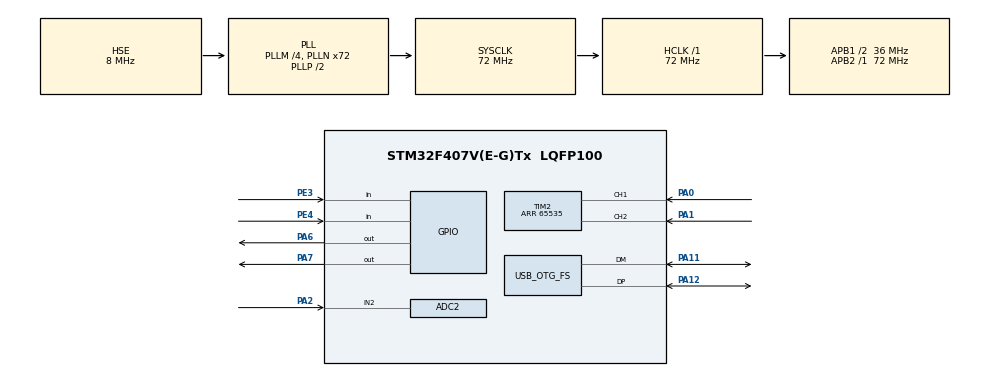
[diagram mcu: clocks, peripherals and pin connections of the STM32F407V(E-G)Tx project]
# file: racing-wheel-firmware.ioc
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ADC2.Channel-0\#ChannelRegularConversion=ADC_CHANNEL_2
ADC2.ClockPrescaler=ADC_CLOCK_SYNC_PCLK_DIV2
ADC2.ContinuousConvMode=ENABLE
ADC2.EOCSelection=ADC_EOC_SEQ_CONV
ADC2.InjNumberOfConversion=0
ADC2.NbrOfConversion=1
ADC2.NbrOfConversionFlag=1
ADC2.Rank-0\#ChannelRegularConversion=1
ADC2.Resolution=ADC_RESOLUTION_8B
ADC2.SamplingTime-0\#ChannelRegularConversion=ADC_SAMPLETIME_480CYCLES
Mcu.Family=STM32F4
Mcu.Name=STM32F407V(E-G)Tx
Mcu.Package=LQFP100
NVIC.OTG_FS_IRQn=true\:0\:0\:false\:false\:true\:false\:true\:true
NVIC.PriorityGroup=NVIC_PRIORITYGROUP_4
PA0-WKUP.Signal=S_TIM2_CH1_ETR
PA1.Signal=S_TIM2_CH2
PA11.Mode=Device_Only
PA11.Signal=USB_OTG_FS_DM
PA12.GPIO_PuPd=GPIO_NOPULL
PA12.Mode=Device_Only
PA12.Signal=USB_OTG_FS_DP
PA13.Mode=Trace_Asynchronous_SW
PA13.Signal=SYS_JTMS-SWDIO
PA14.Mode=Trace_Asynchronous_SW
PA14.Signal=SYS_JTCK-SWCLK
PA2.GPIO_PuPd=GPIO_NOPULL
PA2.Signal=ADCx_IN2
PA6.Signal=GPIO_Output
PA7.Signal=GPIO_Output
PB3.Mode=Trace_Asynchronous_SW
PB3.Signal=SYS_JTDO-SWO
PC14-OSC32_IN.Mode=LSE-External-Oscillator
PC14-OSC32_IN.Signal=RCC_OSC32_IN
PC15-OSC32_OUT.Mode=LSE-External-Oscillator
PC15-OSC32_OUT.Signal=RCC_OSC32_OUT
PE3.GPIO_PuPd=GPIO_PULLUP
PE3.Signal=GPIO_Input
PE4.GPIO_PuPd=GPIO_PULLUP
PE4.Signal=GPIO_Input
PH0-OSC_IN.Mode=HSE-External-Oscillator
PH0-OSC_IN.Signal=RCC_OSC_IN
PH1-OSC_OUT.Mode=HSE-External-Oscillator
PH1-OSC_OUT.Signal=RCC_OSC_OUT
ProjectManager.HeapSize=0x200
ProjectManager.StackSize=0x400
ProjectManager.TargetToolchain=STM32CubeIDE
RCC.48MHZClocksFreq_Value=48000000
RCC.AHBFreq_Value=72000000
RCC.APB1CLKDivider=RCC_HCLK_DIV2
RCC.APB1Freq_Value=36000000
RCC.APB1TimFreq_Value=72000000
RCC.APB2Freq_Value=72000000
RCC.APB2TimFreq_Value=72000000
RCC.CortexFreq_Value=72000000
RCC.HCLKFreq_Value=72000000
RCC.HSE_VALUE=8000000
RCC.HSI_VALUE=16000000
RCC.PLLM=4
RCC.PLLN=72
RCC.PLLQ=3
RCC.SYSCLKFreq_VALUE=72000000
RCC.SYSCLKSource=RCC_SYSCLKSOURCE_PLLCLK
RCC.VCOOutputFreq_Value=144000000
SH.ADCx_IN2.0=ADC2_IN2,IN2
SH.S_TIM2_CH1_ETR.0=TIM2_CH1,Encoder_Interface
SH.S_TIM2_CH2.0=TIM2_CH2,Encoder_Interface
TIM2.AutoReloadPreload=TIM_AUTORELOAD_PRELOAD_ENABLE
TIM2.EncoderMode=TIM_ENCODERMODE_TI12
TIM2.Period=65535
USB_DEVICE.CLASS_NAME_FS=CUSTOM_HID
USB_DEVICE.MANUFACTURER_STRING-CUSTOM_HID_FS=OMP
USB_DEVICE.PID_CUSTOMHID_FS=0x5750
USB_DEVICE.PRODUCT_STRING_CUSTOMHID_FS=OMP Racing wheel
USB_DEVICE.USBD_CUSTOMHID_OUTREPORT_BUF_SIZE-CUSTOM_HID_FS=64
USB_DEVICE.USBD_CUSTOM_HID_REPORT_DESC_SIZE-CUSTOM_HID_FS=46
USB_DEVICE.VID-CUSTOM_HID_FS=0x483
USB_DEVICE.VirtualMode-CUSTOM_HID_FS=CustomHid
USB_DEVICE.VirtualModeFS=Custom_Hid_FS
USB_OTG_FS.VirtualMode=Device_Only
VP_USB_DEVICE_VS_USB_DEVICE_CUSTOM_HID_FS.Mode=CUSTOM_HID_FS
board=custom

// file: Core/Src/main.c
/* USER CODE BEGIN Header */
/**
  ******************************************************************************
  * @file           : main.c
  * @brief          : Main program body
  ******************************************************************************
  * @attention
  *
  * Copyright (c) 2023 STMicroelectronics.
  * All rights reserved.
  *
  * This software is licensed under terms that can be found in the LICENSE file
  * in the root directory of this software component.
  * If no LICENSE file comes with this software, it is provided AS-IS.
  *
  ******************************************************************************
  */
/* USER CODE END Header */
#include "main.h"
#include "usb_device.h"

ADC_HandleTypeDef hadc2;

TIM_HandleTypeDef htim2;

void SystemClock_Config(void);
static void MX_GPIO_Init(void);
static void MX_ADC2_Init(void);
static void MX_TIM2_Init(void);

/* USER CODE BEGIN 0 */

// [DEBUG] printf
// _write is internally used by printf
// We point it to now use the Instrumentation Trace Macrocell (ITM)
// Which is wired to SWO
int _write(int file,char* data,int len){
    for(int i = 0;i<len;i++){
        ITM_SendChar(*data++);
    }
    return len;
}

/* USER CODE END 0 */

int main(void)
{

  /* MCU Configuration--------------------------------------------------------*/

  /* Reset of all peripherals, Initializes the Flash interface and the Systick. */
  HAL_Init();

  /* Configure the system clock */
  SystemClock_Config();

  /* USER CODE BEGIN SysInit */
  __HAL_RCC_TIM2_CLK_ENABLE();
  /* USER CODE END SysInit */

  /* Initialize all configured peripherals */
  MX_GPIO_Init();
  MX_USB_DEVICE_Init();
  MX_ADC2_Init();
  MX_TIM2_Init();

  /* Infinite loop */
  /* USER CODE BEGIN WHILE */
  while (1)
  {
      uint32_t enc = TIM2->CNT;
//      printf("Encoder Ticks = %lu\n\r", enc);
      HAL_ADC_PollForConversion(&hadc2, HAL_MAX_DELAY);
      uint32_t accel = HAL_ADC_GetValue(&hadc2);
//      printf("Accelerator = %lu\n\r", accel);

    /* USER CODE END WHILE */

  }
}

void SystemClock_Config(void)
{
  RCC_OscInitTypeDef RCC_OscInitStruct = {0};
  RCC_ClkInitTypeDef RCC_ClkInitStruct = {0};

  /** Configure the main internal regulator output voltage
  */
  __HAL_RCC_PWR_CLK_ENABLE();
  __HAL_PWR_VOLTAGESCALING_CONFIG(PWR_REGULATOR_VOLTAGE_SCALE1);

  /** Initializes the RCC Oscillators according to the specified parameters
  * in the RCC_OscInitTypeDef structure.
  */
  RCC_OscInitStruct.OscillatorType = RCC_OSCILLATORTYPE_HSE;
  RCC_OscInitStruct.HSEState = RCC_HSE_ON;
  RCC_OscInitStruct.PLL.PLLState = RCC_PLL_ON;
  RCC_OscInitStruct.PLL.PLLSource = RCC_PLLSOURCE_HSE;
  RCC_OscInitStruct.PLL.PLLM = 4;
  RCC_OscInitStruct.PLL.PLLN = 72;
  RCC_OscInitStruct.PLL.PLLP = RCC_PLLP_DIV2;
  RCC_OscInitStruct.PLL.PLLQ = 3;
  if (HAL_RCC_OscConfig(&RCC_OscInitStruct) != HAL_OK)
  {
    Error_Handler();
  }

  /** Initializes the CPU, AHB and APB buses clocks
  */
  RCC_ClkInitStruct.ClockType = RCC_CLOCKTYPE_HCLK|RCC_CLOCKTYPE_SYSCLK
                              |RCC_CLOCKTYPE_PCLK1|RCC_CLOCKTYPE_PCLK2;
  RCC_ClkInitStruct.SYSCLKSource = RCC_SYSCLKSOURCE_PLLCLK;
  RCC_ClkInitStruct.AHBCLKDivider = RCC_SYSCLK_DIV1;
  RCC_ClkInitStruct.APB1CLKDivider = RCC_HCLK_DIV2;
  RCC_ClkInitStruct.APB2CLKDivider = RCC_HCLK_DIV1;

  if (HAL_RCC_ClockConfig(&RCC_ClkInitStruct, FLASH_LATENCY_2) != HAL_OK)
  {
    Error_Handler();
  }
}

static void MX_ADC2_Init(void)
{

  ADC_ChannelConfTypeDef sConfig = {0};

  /** Configure the global features of the ADC (Clock, Resolution, Data Alignment and number of conversion)
  */
  hadc2.Instance = ADC2;
  hadc2.Init.ClockPrescaler = ADC_CLOCK_SYNC_PCLK_DIV2;
  hadc2.Init.Resolution = ADC_RESOLUTION_8B;
  hadc2.Init.ScanConvMode = DISABLE;
  hadc2.Init.ContinuousConvMode = ENABLE;
  hadc2.Init.DiscontinuousConvMode = DISABLE;
  hadc2.Init.ExternalTrigConvEdge = ADC_EXTERNALTRIGCONVEDGE_NONE;
  hadc2.Init.ExternalTrigConv = ADC_SOFTWARE_START;
  hadc2.Init.DataAlign = ADC_DATAALIGN_RIGHT;
  hadc2.Init.NbrOfConversion = 1;
  hadc2.Init.DMAContinuousRequests = DISABLE;
  hadc2.Init.EOCSelection = ADC_EOC_SEQ_CONV;
  if (HAL_ADC_Init(&hadc2) != HAL_OK)
  {
    Error_Handler();
  }

  /** Configure for the selected ADC regular channel its corresponding rank in the sequencer and its sample time.
  */
  sConfig.Channel = ADC_CHANNEL_2;
  sConfig.Rank = 1;
  sConfig.SamplingTime = ADC_SAMPLETIME_480CYCLES;
  if (HAL_ADC_ConfigChannel(&hadc2, &sConfig) != HAL_OK)
  {
    Error_Handler();
  }
  /* USER CODE BEGIN ADC2_Init 2 */
    HAL_ADC_Start(&hadc2);
  /* USER CODE END ADC2_Init 2 */

}

static void MX_TIM2_Init(void)
{

  TIM_Encoder_InitTypeDef sConfig = {0};
  TIM_MasterConfigTypeDef sMasterConfig = {0};

  htim2.Instance = TIM2;
  htim2.Init.Prescaler = 0;
  htim2.Init.CounterMode = TIM_COUNTERMODE_UP;
  htim2.Init.Period = 65535;
  htim2.Init.ClockDivision = TIM_CLOCKDIVISION_DIV1;
  htim2.Init.AutoReloadPreload = TIM_AUTORELOAD_PRELOAD_ENABLE;
  sConfig.EncoderMode = TIM_ENCODERMODE_TI12;
  sConfig.IC1Polarity = TIM_ICPOLARITY_RISING;
  sConfig.IC1Selection = TIM_ICSELECTION_DIRECTTI;
  sConfig.IC1Prescaler = TIM_ICPSC_DIV1;
  sConfig.IC1Filter = 0;
  sConfig.IC2Polarity = TIM_ICPOLARITY_RISING;
  sConfig.IC2Selection = TIM_ICSELECTION_DIRECTTI;
  sConfig.IC2Prescaler = TIM_ICPSC_DIV1;
  sConfig.IC2Filter = 0;
  if (HAL_TIM_Encoder_Init(&htim2, &sConfig) != HAL_OK)
  {
    Error_Handler();
  }
  sMasterConfig.MasterOutputTrigger = TIM_TRGO_RESET;
  sMasterConfig.MasterSlaveMode = TIM_MASTERSLAVEMODE_DISABLE;
  if (HAL_TIMEx_MasterConfigSynchronization(&htim2, &sMasterConfig) != HAL_OK)
  {
    Error_Handler();
  }
  /* USER CODE BEGIN TIM2_Init 2 */
    HAL_TIM_Encoder_Start(&htim2,ALL_CHANNELS);
  /* USER CODE END TIM2_Init 2 */

}

static void MX_GPIO_Init(void)
{
  GPIO_InitTypeDef GPIO_InitStruct = {0};

  /* GPIO Ports Clock Enable */
  __HAL_RCC_GPIOE_CLK_ENABLE();
  __HAL_RCC_GPIOC_CLK_ENABLE();
  __HAL_RCC_GPIOH_CLK_ENABLE();
  __HAL_RCC_GPIOA_CLK_ENABLE();
  __HAL_RCC_GPIOB_CLK_ENABLE();

  /*Configure GPIO pin Output Level */
  HAL_GPIO_WritePin(GPIOA, GPIO_PIN_6|GPIO_PIN_7, GPIO_PIN_RESET);

  /*Configure GPIO pins : PE3 PE4 */
  GPIO_InitStruct.Pin = GPIO_PIN_3|GPIO_PIN_4;
  GPIO_InitStruct.Mode = GPIO_MODE_INPUT;
  GPIO_InitStruct.Pull = GPIO_PULLUP;
  HAL_GPIO_Init(GPIOE, &GPIO_InitStruct);

  /*Configure GPIO pins : PA6 PA7 */
  GPIO_InitStruct.Pin = GPIO_PIN_6|GPIO_PIN_7;
  GPIO_InitStruct.Mode = GPIO_MODE_OUTPUT_PP;
  GPIO_InitStruct.Pull = GPIO_NOPULL;
  GPIO_InitStruct.Speed = GPIO_SPEED_FREQ_LOW;
  HAL_GPIO_Init(GPIOA, &GPIO_InitStruct);

}

void Error_Handler(void)
{
  /* USER CODE BEGIN Error_Handler_Debug */
  /* User can add his own implementation to report the HAL error return state */
  __disable_irq();
  printf("SOME ERROR OCCURED IDK");
  while (1)
  {
  }
  /* USER CODE END Error_Handler_Debug */
}
